AUTOSAR XML (schema 4-1-0)
standard types defined: uint8, sint8, uint16, sint16
package /Cluster
  can cluster CAN
    can physical channel CAN
      frame FRAME_muxTestFrame: id 0x4, from TEST_ECU, to CCL_TEST, frame-length=7, can-addressing-mode=STANDARD
        pdu PDU_muxTestFrame: length=7
          signal myMuxer: start 53, 3 bit, little-endian, base-type=uint8, compu {0=off, 1..5=low range, 6..10=high range; unit myMuxer}, unit=myMuxer, to CCL_TEST
          signal muxSig4: start 25, 7 bit, little-endian, base-type=sint8, compu {phys=raw for raw 0; unit muxSig4}, unit=muxSig4, to CCL_TEST
          signal muxSig3: start 16, 9 bit, little-endian, base-type=uint16, compu {phys=raw for raw 0; unit muxSig3}, unit=muxSig3, to CCL_TEST
          signal muxSig2: start 15, 8 bit, big-endian, base-type=sint8, compu {phys=raw for raw 0; unit muxSig2}, unit=muxSig2, to CCL_TEST
          signal muxSig1: start 0, 8 bit, little-endian, base-type=sint8, compu {phys=raw for raw 0; unit muxSig1}, unit=muxSig1, to CCL_TEST
          signal muxSig5: start 22, 7 bit, little-endian, base-type=sint8, compu {phys=raw for raw 0; unit muxSig5}, unit=muxSig5, to CCL_TEST
          signal muxSig6: start 32, 9 bit, little-endian, base-type=uint16, compu {phys=raw for raw 0; unit muxSig6}, unit=muxSig6, to CCL_TEST
          signal muxSig7: start 2, 8 bit, big-endian, base-type=sint8, compu {phys=raw for raw 0; unit muxSig7}, unit=muxSig7, to CCL_TEST
          signal muxSig8: start 0, 6 bit, little-endian, base-type=sint8, compu {phys=raw for raw 0; unit muxSig8}, unit=muxSig8, to CCL_TEST
          signal muxSig9: start 40, 8 bit, little-endian, base-type=sint8, compu {phys=raw for raw 0; unit muxSig9}, unit=muxSig9, to CCL_TEST
      frame FRAME_testFrameFloat: id 0x3, from TEST_ECU, to CCL_TEST, frame-length=8, can-addressing-mode=STANDARD
        pdu PDU_testFrameFloat: length=8
          signal floatSignal2: start 32, 32 bit, little-endian, base-type=single, compu {phys=raw for raw 0; unit floatSignal2}, unit=floatSignal2, to CCL_TEST
          signal floatSignal1: start 7, 32 bit, big-endian, base-type=single, compu {phys=raw for raw 0; unit floatSignal1}, unit=floatSignal1, to CCL_TEST
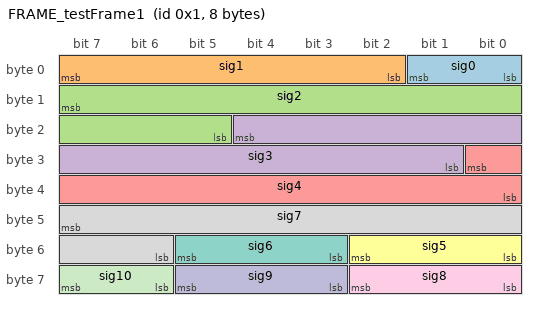
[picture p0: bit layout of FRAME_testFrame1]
      frame FRAME_testFrame1: id 0x1, from TEST_ECU, to CCL_TEST, frame-length=8, can-addressing-mode=STANDARD
        pdu PDU_testFrame1: length=8
          signal sig0: start 1, 2 bit, big-endian, base-type=uint8, compu {phys=raw for raw 0; unit sig0}, unit=sig0, to CCL_TEST
          signal sig1: start 7, 6 bit, big-endian, base-type=uint8, compu {phys=raw for raw 0; unit sig1}, unit=sig1, to CCL_TEST
          signal sig2: start 15, 11 bit, big-endian, base-type=uint16, compu {phys=raw for raw 0; unit sig2}, unit=sig2, to CCL_TEST
          signal sig3: start 20, 12 bit, big-endian, base-type=uint16, compu {phys=raw for raw 0; unit sig3}, unit=sig3, to CCL_TEST
          signal sig4: start 24, 9 bit, big-endian, base-type=uint16, compu {phys=raw for raw 0; unit sig4}, unit=sig4, to CCL_TEST
          signal sig5: start 50, 3 bit, big-endian, base-type=uint8, compu {phys=raw for raw 0; unit sig5}, unit=sig5, to CCL_TEST
          signal sig6: start 53, 3 bit, big-endian, base-type=uint8, compu {phys=raw for raw 0; unit sig6}, unit=sig6, to CCL_TEST
          signal sig7: start 47, 10 bit, big-endian, base-type=uint16, compu {phys=raw for raw 0; unit sig7}, unit=sig7, to CCL_TEST
          signal sig8: start 58, 3 bit, big-endian, base-type=uint8, compu {phys=raw for raw 0; unit sig8}, unit=sig8, to CCL_TEST
          signal sig9: start 61, 3 bit, big-endian, base-type=uint8, compu {phys=raw for raw 0; unit sig9}, unit=sig9, to CCL_TEST
          signal sig10: start 63, 2 bit, big-endian, base-type=uint8, compu {phys=raw for raw 0; unit sig10}, unit=sig10, to CCL_TEST
          mapping M_SIGGRP_auto: i-signal-group=SIGGRP_auto
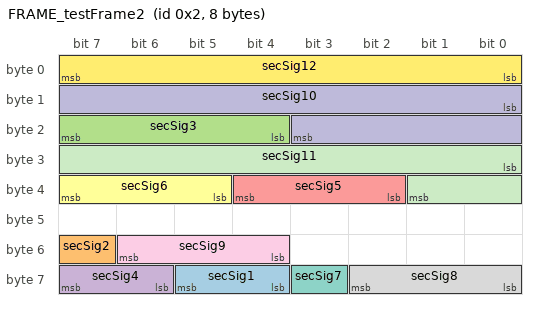
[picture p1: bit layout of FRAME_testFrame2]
      frame FRAME_testFrame2: id 0x2, from TEST_ECU, to CCL_TEST, frame-length=8, can-addressing-mode=STANDARD
        pdu PDU_testFrame2: length=8
          signal secSig1: start 60, 2 bit, little-endian, base-type=uint8, compu {phys=raw for raw 0; unit secSig1}, unit=secSig1, to CCL_TEST
          signal secSig2: start 55, 1 bit, little-endian, base-type=uint8, compu {phys=raw for raw 0; unit secSig2}, unit=secSig2, to CCL_TEST
          signal secSig3: start 20, 4 bit, little-endian, base-type=uint8, compu {phys=raw for raw 0; unit secSig3}, unit=secSig3, to CCL_TEST
          signal secSig4: start 62, 2 bit, little-endian, base-type=uint8, compu {phys=raw for raw 0; unit secSig4}, unit=secSig4, to CCL_TEST
          signal secSig5: start 34, 3 bit, little-endian, base-type=uint8, compu {phys=raw for raw 0; unit secSig5}, unit=secSig5, to CCL_TEST
          signal secSig6: start 37, 3 bit, little-endian, base-type=uint8, compu {phys=raw for raw 0; unit secSig6}, unit=secSig6, to CCL_TEST
          signal secSig7: start 59, 1 bit, little-endian, base-type=sint8, compu {phys=raw for raw 0; unit secSig7}, unit=secSig7, to CCL_TEST
          signal secSig8: start 56, 3 bit, little-endian, base-type=uint8, compu {phys=raw for raw 0; unit secSig8}, unit=secSig8, to CCL_TEST
          signal secSig9: start 52, 3 bit, little-endian, base-type=uint8, compu {phys=raw for raw 0; unit secSig9}, unit=secSig9, to CCL_TEST
          signal secSig10: start 8, 12 bit, little-endian, base-type=uint16, compu {phys=raw for raw 0; unit secSig10}, unit=secSig10, to CCL_TEST
          signal secSig11: start 24, 10 bit, little-endian, base-type=sint16, compu {phys=raw for raw 0; unit secSig11}, unit=secSig11, to CCL_TEST
          signal secSig12: start 0, 8 bit, little-endian, base-type=uint8, compu {phys=raw for raw 0; unit secSig12}, unit=secSig12, to CCL_TEST
package /ISignal
  i signal group SIGGRP_auto: system-signal-group=SIGGRP_system, i-signal=[sig0, sig1]
package /DataType
  base type single: category=FIXED_LENGTH, base-type-size=32, base-type-encoding=IEEE754
package /DataType/Unit
  35 x unit:
    myMuxer
    muxSig4
    muxSig3
    muxSig2
    muxSig1
    muxSig{5..9}
    floatSignal2
    floatSignal1
    sig{0..10}
    secSig{1..12}
package /ECU
  ecu instance CCL_TEST: associated-com-i-pdu-group=CCL_TEST_Rx
    can communication connector CN_CCL_TEST
  ecu instance TEST_ECU: associated-com-i-pdu-group=TEST_ECU_Tx
    can communication connector CN_TEST_ECU
package /IPDUGroup
  i signal i pdu group TEST_ECU_Tx: communication-direction=OUT, i-signal-i-pdus=[PDU_muxTestFrame, PDU_testFrameFloat, PDU_testFrame1, PDU_testFrame2]
  i signal i pdu group CCL_TEST_Rx: communication-direction=IN, i-signal-i-pdus=[PDU_muxTestFrame, PDU_testFrameFloat, PDU_testFrame1, PDU_testFrame2]
